VERSION ""

NS_ :

BS_:

BU_: Aussenlicht Kuehlkreislaufsteuerung System

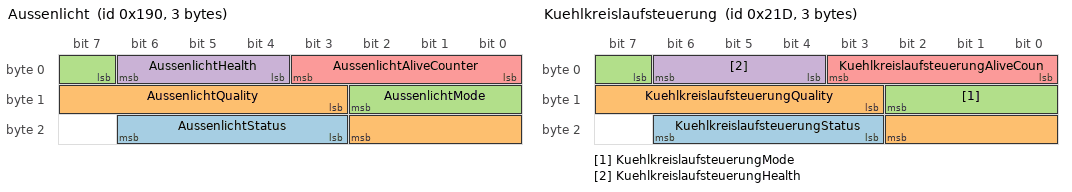
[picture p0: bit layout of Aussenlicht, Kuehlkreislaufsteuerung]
BO_ 400 Aussenlicht: 3 Aussenlicht
 SG_ AussenlichtStatus : 19|4@1+ (1,0) [0.0|15.0] "code"  System
 SG_ AussenlichtQuality : 11|8@1+ (0.5,0.0) [0.0|100.0] "%"  System
 SG_ AussenlichtMode : 7|4@1+ (1,0) [0.0|15.0] "code"  System
 SG_ AussenlichtHealth : 4|3@1+ (1,0) [0.0|7.0] "code"  System
 SG_ AussenlichtAliveCounter : 0|4@1+ (1,0) [0.0|15.0] "count"  System

BO_ 541 Kuehlkreislaufsteuerung: 3 Kuehlkreislaufsteuerung
 SG_ KuehlkreislaufsteuerungStatus : 19|4@1+ (1,0) [0.0|15.0] "code"  System
 SG_ KuehlkreislaufsteuerungQuality : 11|8@1+ (0.5,0.0) [0.0|100.0] "%"  System
 SG_ KuehlkreislaufsteuerungMode : 7|4@1+ (1,0) [0.0|15.0] "code"  System
 SG_ KuehlkreislaufsteuerungHealth : 4|3@1+ (1,0) [0.0|7.0] "code"  System
 SG_ KuehlkreislaufsteuerungAliveCoun : 0|4@1+ (1,0) [0.0|15.0] "count"  System

CM_ BO_ 400 "CanonicalMessage=03c91d1d-fd4c-48e9-a291-764fe52f14bb; Network=Klima_Thermik_07-S01; Technology=can_fd";
CM_ SG_ 400 AussenlichtStatus "CanonicalSignal=1a77f9fc-e3e2-49f0-af41-7fa981b57e2c";
CM_ SG_ 400 AussenlichtQuality "CanonicalSignal=b4b3c999-faa1-4300-81c8-7d1a71050a4d";
CM_ SG_ 400 AussenlichtMode "CanonicalSignal=09356fbd-2cb0-4175-96df-00ae2579c2d9";
CM_ SG_ 400 AussenlichtHealth "CanonicalSignal=ee7e42f6-c8cd-4983-947d-1d9e9a4799a2";
CM_ SG_ 400 AussenlichtAliveCounter "CanonicalSignal=7bc20f1c-8abc-4a32-bf95-9afb5b33efe5";
CM_ BO_ 541 "CanonicalMessage=ba8e3aaf-38c2-4902-958a-0c7bf335932a; Network=Klima_Thermik_07-S01; Technology=can_fd";
CM_ SG_ 541 KuehlkreislaufsteuerungStatus "CanonicalSignal=a77a9f78-622a-4012-b150-ae9df3cb1820";
CM_ SG_ 541 KuehlkreislaufsteuerungQuality "CanonicalSignal=86667eb6-52f0-4b26-890a-f1f5ab6e847a";
CM_ SG_ 541 KuehlkreislaufsteuerungMode "CanonicalSignal=07021cea-5a11-408c-b9cc-44b53fddf856";
CM_ SG_ 541 KuehlkreislaufsteuerungHealth "CanonicalSignal=c6a1ff01-ac5d-4bd1-b782-49ddb83787c5";
CM_ SG_ 541 KuehlkreislaufsteuerungAliveCoun "CanonicalSignal=cd8db79d-7175-43b0-b921-bee20fd408f3";
BA_DEF_ BO_  "VFrameFormat" ENUM  "StandardCAN","ExtendedCAN","StandardCAN_FD","ExtendedCAN_FD";
BA_DEF_DEF_  "VFrameFormat" "0";
BA_ "VFrameFormat" BO_ 400 2;
BA_ "VFrameFormat" BO_ 541 2;
